# ESP32-P4 register map
Vendor: ESPRESSIF SYSTEMS (SHANGHAI) CO., LTD.; Series: ESP32 P-Series; File version: 3
CPU: RV32IMAFC r0p0, little endian, no MPU, FPU, 0 interrupt priority bits
Address unit: 32 bits
Registers are 32-bit, read-write, reset 0x0 unless marked. A register's access mark holds for its fields unless they carry their own. Offsets are from the block's base; [hi:lo] are bit positions; lines under a group give offsets from that group; {n}, {i} and the like mark numbered series.

## LEDC — LED Control PWM (Pulse Width Modulation)
Base 0x500D3000
{0x0+0x14*i} CH{i} (i=0..7) group — Cluster CH{i}, containing CH?_CONF0, CH?_HPOINT, CH?_DUTY, CH?_CONF1, CH?_DUTY_R
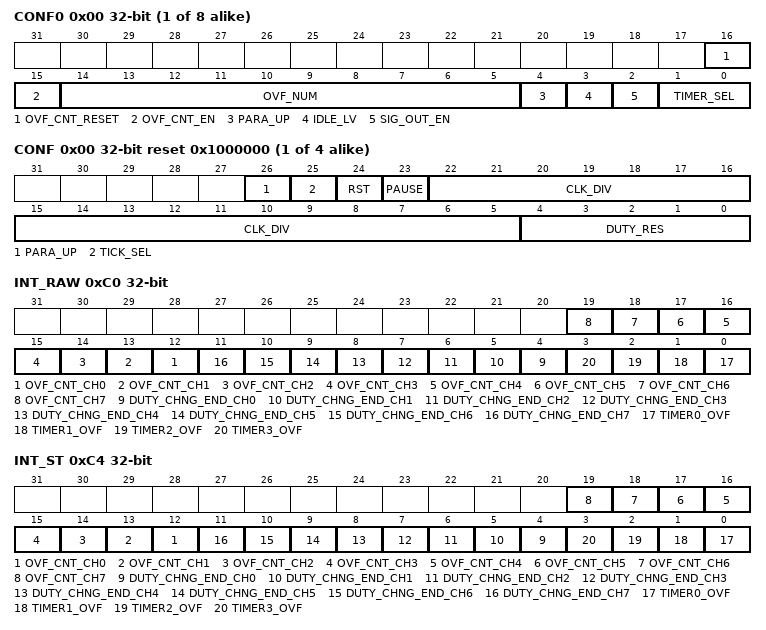
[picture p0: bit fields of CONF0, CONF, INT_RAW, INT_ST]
  0x00 CONF0 access per field — Configuration register 0 for channel 0
    [16] OVF_CNT_RESET wo — Configures whether or not to reset the ovf_cnt of channel %s.\\0: Invalid. No effect\\1: Reset the ovf_cnt
    [15] OVF_CNT_EN rw — Configures whether or not to enable the ovf_cnt of channel %s.\\0: Disable\\1: Enable
    [14:5] OVF_NUM rw — Configures the maximum times of overflow minus 1.The LEDC_OVF_CNT_CH%s_INT interrupt will be triggered when channel %s overflows for (LEDC_OVF_NUM_CH%s + 1) times.
    [4] PARA_UP wo — Configures whether or not to update LEDC_HPOINT_CH%s, LEDC_DUTY_START_CH%s, LEDC_SIG_OUT_EN_CH%s, LEDC_TIMER_SEL_CH%s, LEDC_DUTY_NUM_CH%s, LEDC_DUTY_CYCLE_CH%s, LEDC_DUTY_SCALE_CH%s, LEDC_DUTY_INC_CH%s, and LEDC_OVF_CNT_EN_CH%s fields for channel %s, and will be automatically cleared by hardware.\\0: Invalid. No effect\\1: Update
    [3] IDLE_LV rw — Configures the output value when channel %s is inactive. Valid only when LEDC_SIG_OUT_EN_CH%s is 0.\\0: Output level is low\\1: Output level is high
    [2] SIG_OUT_EN rw — Configures whether or not to enable signal output on channel %s.\\0: Signal output disable\\1: Signal output enable
    [1:0] TIMER_SEL rw — Configures which timer is channel %s selected.\\0: Select timer0\\1: Select timer1\\2: Select timer2\\3: Select timer3
  0x04 HPOINT — High point register for channel 0
    [19:0] HPOINT — Configures high point of signal output on channel %s. The output value changes to high when the selected timers has reached the value specified by this register.
  0x08 DUTY — Initial duty cycle register for channel 0
    [24:0] DUTY — Configures the duty of signal output on channel %s.
  0x0C CONF1 — Configuration register 1 for channel 0
    [31] DUTY_START — Configures whether the duty cycle fading configurations take effect.\\0: Not take effect\\1: Take effect
  0x10 DUTY_R ro — Current duty cycle register for channel 0
    [24:0] DUTY_R — Represents the current duty of output signal on channel %s.
{0xA0+8i} TIMER{i} (i=0..3) group — Cluster TIMER{i}, containing TIMER?_CONF, TIMER?_VALUE
  0x00 CONF access per field reset 0x1000000 — Timer 0 configuration register
    [26] PARA_UP wo — Configures whether or not to update LEDC_CLK_DIV_TIMER%s and LEDC_TIMER%s_DUTY_RES.\\0: Invalid. No effect\\1: Update
    [25] TICK_SEL rw — Configures which clock is timer %s selected. Unused.
    [24] RST rw — Configures whether or not to reset timer %s. The counter will show 0 after reset.\\0: Not reset\\1: Reset
    [23] PAUSE rw — Configures whether or not to pause the counter in timer %s.\\0: Normal\\1: Pause
    [22:5] CLK_DIV rw — Configures the divisor for the divider in timer %s.The least significant eight bits represent the fractional part.
    [4:0] DUTY_RES rw — Configures the range of the counter in timer %s.
  0x04 VALUE ro — Timer 0 current counter value register
    [19:0] CNT — Represents the current counter value of timer %s.
0xC0 INT_RAW — Interrupt raw status register
  [n+12] OVF_CNT_CH{n} (n=0..7) — Interrupt raw bit for channel {n}. Triggered when the OVF_CNT has reached the value specified by LEDC.CHx.CONF0.OVF_NUM.
  [n+4] DUTY_CHNG_END_CH{n} (n=0..7) — Interrupt raw bit for channel {n}. Triggered when the gradual change of duty has finished.
  [n] TIMER{n}_OVF (n=0..3) — Triggered when the timer{n} has reached its maximum counter value.
0xC4 INT_ST ro — Interrupt masked status register
  [n+12] OVF_CNT_CH{n} (n=0..7) — This is the masked interrupt status bit for the LEDC.INT_RAW.OVF_CNT_CH{n} interrupt when LEDC.INT_ENA.OVF_CNT_CHx is set to 1.
  [n+4] DUTY_CHNG_END_CH{n} (n=0..7) — This is the masked interrupt status bit for the DUTY_CHNG_END_CH{n} interrupt when LEDC.INT_ENA.DUTY_CHNG_END_CHx is set to 1.
  [n] TIMER{n}_OVF (n=0..3) — This is the masked interrupt status bit for the TIMER{n}_OVF interrupt when LEDC.INT_ENA.TIMERx_OVF is set to 1.
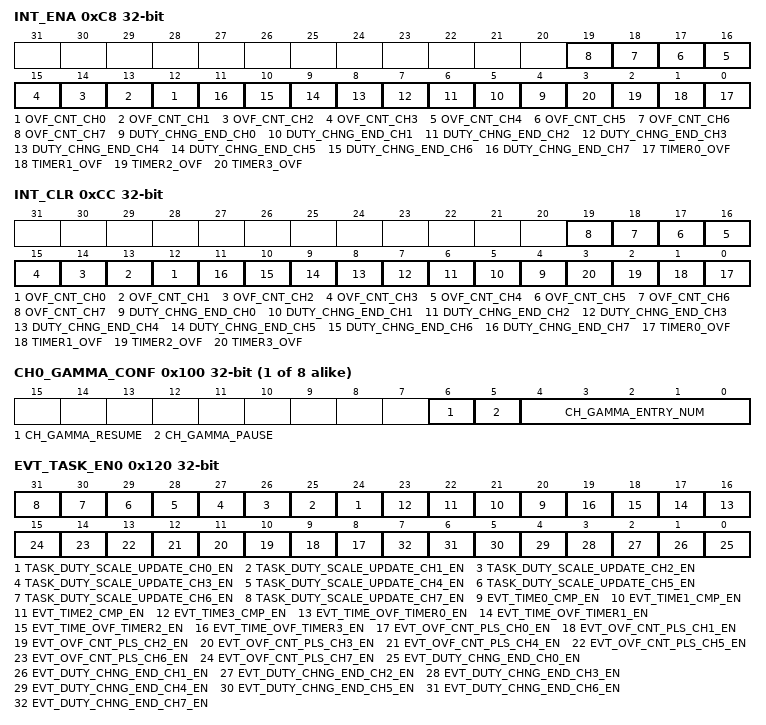
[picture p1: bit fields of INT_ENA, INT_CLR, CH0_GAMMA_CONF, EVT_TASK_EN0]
0xC8 INT_ENA — Interrupt enable register
  [n+12] OVF_CNT_CH{n} (n=0..7) — The interrupt enable bit for the OVF_CNT_CH{n} interrupt.
  [n+4] DUTY_CHNG_END_CH{n} (n=0..7) — The interrupt enable bit for the DUTY_CHNG_END_CH{n} interrupt.
  [n] TIMER{n}_OVF (n=0..3) — The interrupt enable bit for the TIMER{n}_OVF interrupt.
0xCC INT_CLR wo — Interrupt clear register
  [n+12] OVF_CNT_CH{n} (n=0..7) write-1-clears — Set this bit to clear the OVF_CNT_CH{n} interrupt.
  [n+4] DUTY_CHNG_END_CH{n} (n=0..7) write-1-clears — Set this bit to clear the DUTY_CHNG_END_CH{n} interrupt.
  [n] TIMER{n}_OVF (n=0..3) write-1-clears — Set this bit to clear the TIMER{n}_OVF interrupt.
{0x100+4i} CH{i}_GAMMA_CONF (i=0..7) access per field — Ledc ch{i} gamma config register.
  [6] CH_GAMMA_RESUME wo — Configures whether or nor to resume duty cycle fading of LEDC ch%s.\\0: Invalid. No effect\\1: Resume
  [5] CH_GAMMA_PAUSE wo — Configures whether or not to pause duty cycle fading of LEDC ch%s.\\0: Invalid. No effect\\1: Pause
  [4:0] CH_GAMMA_ENTRY_NUM rw — Configures the number of duty cycle fading rages for LEDC ch%s.
0x120 EVT_TASK_EN0 — Ledc event task enable bit register0.
  [n+24] TASK_DUTY_SCALE_UPDATE_CH{n}_EN (n=0..7) — Configures whether or not to enable the ledc_ch{n}_duty_scale_update task.\\0: Disable\\1: Enable
  [n+20] EVT_TIME{n}_CMP_EN (n=0..3) — Configures whether or not to enable the ledc_timer{n}_cmp event.\\0: Disable\\1: Enable
  [n+16] EVT_TIME_OVF_TIMER{n}_EN (n=0..3) — Configures whether or not to enable the ledc_timer{n}_ovf event.\\0: Disable\\1: Enable
  [n+8] EVT_OVF_CNT_PLS_CH{n}_EN (n=0..7) — Configures whether or not to enable the ledc_ch{n}_ovf_cnt_pls event.\\0: Disable\\1: Enable
  [n] EVT_DUTY_CHNG_END_CH{n}_EN (n=0..7) — Configures whether or not to enable the ledc_ch{n}_duty_chng_end event.\\0: Disable\\1: Enable
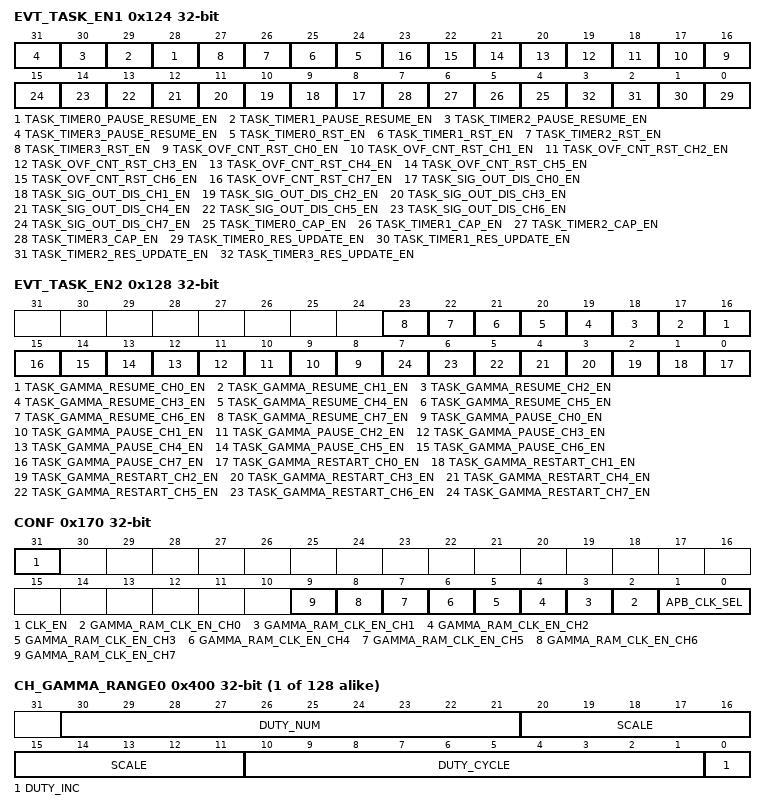
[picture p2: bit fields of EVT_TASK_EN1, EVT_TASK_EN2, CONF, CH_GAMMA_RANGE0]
0x124 EVT_TASK_EN1 — Ledc event task enable bit register1.
  [n+28] TASK_TIMER{n}_PAUSE_RESUME_EN (n=0..3) — Configures whether or not to enable ledc_timer{n}_pause_resume task.\\0: Disable\\1: Enable
  [n+24] TASK_TIMER{n}_RST_EN (n=0..3) — Configures whether or not to enable ledc_timer{n}_rst task.\\0: Disable\\1: Enable
  [n+16] TASK_OVF_CNT_RST_CH{n}_EN (n=0..7) — Configures whether or not to enable ledc_ch{n}_ovf_cnt_rst task.\\0: Disable\\1: Enable
  [n+8] TASK_SIG_OUT_DIS_CH{n}_EN (n=0..7) — Configures whether or not to enable ledc_ch{n}_sig_out_dis task.\\0: Disable\\1: Enable
  [n+4] TASK_TIMER{n}_CAP_EN (n=0..3) — Configures whether or not to enable ledc_timer{n}_cap task.\\0: Disable\\1: Enable
  [n] TASK_TIMER{n}_RES_UPDATE_EN (n=0..3) — Configures whether or not to enable ledc_timer{n}_res_update task.\\0: Disable\\1: Enable
0x128 EVT_TASK_EN2 — Ledc event task enable bit register2.
  [n+16] TASK_GAMMA_RESUME_CH{n}_EN (n=0..7) — Configures whether or not to enable ledc_ch{n}_gamma_resume task.\\0: Disable\\1: Enable
  [n+8] TASK_GAMMA_PAUSE_CH{n}_EN (n=0..7) — Configures whether or not to enable ledc_ch{n}_gamma_pause task.\\0: Disable\\1: Enable
  [n] TASK_GAMMA_RESTART_CH{n}_EN (n=0..7) — Configures whether or not to enable ledc_ch{n}_gamma_restart task.\\0: Disable\\1: Enable
{0x140+4i} TIMER{i}_CMP (i=0..3) — Ledc timer{i} compare value register.
  [19:0] TIMER_CMP — Configures the comparison value for LEDC timer%s.
{0x150+4i} TIMER{i}_CNT_CAP (i=0..3) ro — Ledc timer{i} captured count value register.
  [19:0] TIMER_CNT_CAP — Represents the captured LEDC timer%s count value.
0x170 CONF — LEDC global configuration register
  [31] CLK_EN — Configures whether or not to open register clock gate.\\0: Open the clock gate only when application writes registers\\1: Force open the clock gate for register
  [n+2] GAMMA_RAM_CLK_EN_CH{n} (n=0..7) — Configures whether or not to open LEDC ch{n} gamma ram clock gate.\\0: Open the clock gate only when application writes or reads LEDC ch{n} gamma ram\\1: Force open the clock gate for LEDC ch{n} gamma ram
  [1:0] APB_CLK_SEL — Configures the clock source for the four timers.\\0: APB_CLK\\1: RC_FAST_CLK\\2: XTAL_CLK\\3: Invalid. No clock
0x174 DATE reset 0x2404020 — Version control register
  [27:0] LEDC_DATE — Configures the version.
{0x400+4i} CH_GAMMA_RANGE{i} (i=0..127) — Gamma range word {i} (channel = {i} / 16, range = {i} mod 16)
  [30:21] DUTY_NUM — Duty number
  [20:11] SCALE — Gamma scale
  [10:1] DUTY_CYCLE
  [0] DUTY_INC — Duty increase or decrease
